# SF32LB57x register map
File version: 1.0
CPU: CM33 r0p1, little endian, MPU, FPU, 3 interrupt priority bits
Registers are 32-bit, read-write, reset 0x0 unless marked. A register's access mark holds for its fields unless they carry their own. Offsets are from the block's base; [hi:lo] are bit positions.

## LPTIM1
Base 0x500C1000
Same registers: LPTIM3 0x40042000, LPTIM2 0x500C2000
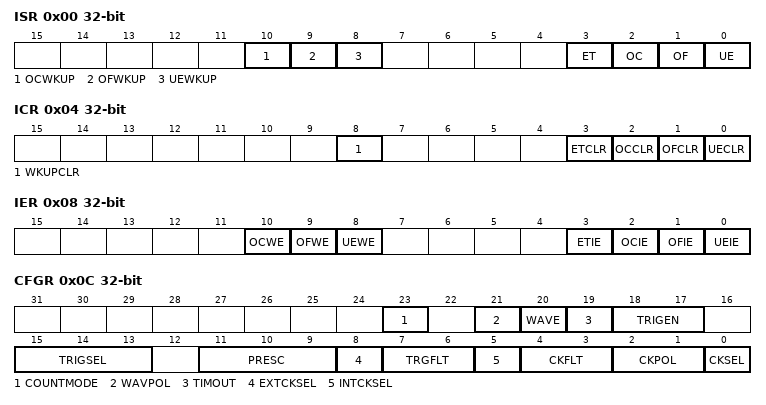
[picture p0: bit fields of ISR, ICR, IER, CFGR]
0x00 ISR — LPTIM interrupt and status register
  [10] OCWKUP — Indicates output compare wakeup occurred The OCWKUP bit is set by hardware when LPTIM_CNT register value reached the LPTIM_CMP register’s value. To clear OCWKUP, first write 0 to the OCWE bit in the LPTIM_IER register to disable, then write 1 to the WKUPCLR bit in the LPTIM_ICR register.
  [9] OFWKUP — Indicates overflow wakeup occurred OFWKUP is set by hardware when LPTIM_CNT register’s value reached the LPTIM_ARR register’s value and count from zero again. To clear OFWKUP, first write 0 to the OFWE bit in the LPTIM_IER register to disable, then write 1 to the WKUPCLR bit in the LPTIM_ICR register.
  [8] UEWKUP — Indicates update event wakeup occurred UEWKUP is set by hardware when an update event was generated (overflow occurred while repetition counter reached zero). To clear UEWKUP, first write 0 to the UEWE bit in the LPTIM_IER register to disable, then write 1 to the WKUPCLR bit in the LPTIM_ICR register.
  [3] ET — External trigger edge event ET is set by hardware to inform application that a valid edge on the selected external trigger input has occurred. If the trigger is ignored because the timer has already started, then this flag is not set. ET flag can be cleared by writing 1 to the ETCLR bit in the LPTIM_ICR register.
  [2] OC — Output compare match The OC bit is set by hardware to inform application that LPTIM_CNT register value reached the LPTIM_CMP register’s value. OC flag can be cleared by writing 1 to the OCCLR bit in the LPTIM_ICR register.
  [1] OF — Overflow occurred OF is set by hardware to inform application that LPTIM_CNT register’s value reached the LPTIM_ARR register’s value and count from zero again. OF flag can be cleared by writing 1 to the OFCLR bit in the LPTIM_ICR register.
  [0] UE — LPTIM update event occurred UE is set by hardware to inform application that an update event was generated when overflow occurred while repetition counter reached zero. UE flag can be cleared by writing 1 to the UECLR bit in the LPTIM_ICR register.
0x04 ICR — LPTIM interrupt and status clear register
  [8] WKUPCLR — wakeup status clear flag Writing 1 to this bit clears all wakeup status flags in the LPTIM_ISR register.
  [3] ETCLR — External trigger valid edge clear flag Writing 1 to this bit clears the ET flag in the LPTIM_ISR register
  [2] OCCLR — Output compare clear flag Writing 1 to this bit clears the OC flag in the LPTIM_ISR register
  [1] OFCLR — Overflow clear flag Writing 1 to this bit clears the OF flag in the LPTIM_ISR register
  [0] UECLR — Update event clear flag Writing 1 to this bit clear the UE flag in the LPTIM_ISR register.
0x08 IER — LPTIM interrupt and wakeup enable register
  [10] OCWE — Output compare Wakeup Enable 0: Output compare wakeup disabled 1: Output compare wakeup enabled
  [9] OFWE — Overflow Wakeup Enable 0: Overflow Wakeup disabled 1: Overflow Wakeup enabled
  [8] UEWE — Update event Wakeup enable 0: Update event Wakeup disabled 1: Update event Wakeup enabled
  [3] ETIE — External trigger valid edge Interrupt Enable 0: External trigger interrupt disabled 1: External trigger interrupt enabled
  [2] OCIE — Output compare Interrupt Enable 0: Output compare interrupt disabled 1: Output compare interrupt enabled
  [1] OFIE — Overflow Interrupt Enable 0: Overflow interrupt disabled 1: Overflow interrupt enabled
  [0] UEIE — Update event interrupt enable 0: Update event interrupt disabled 1: Update event interrupt enabled
0x0C CFGR — LPTIM configuration register
  [23] COUNTMODE — counter mode enabled The COUNTMODE bit selects which clock source is used by the LPTIM to clock the counter: 0: the counter is incremented following each internal clock pulse 1: the counter is incremented following each valid clock pulse on the LPTIM external Input1
  [21] WAVPOL — Waveform shape polarity The WAVEPOL bit controls the output polarity 0: The LPTIM output reflects the compare results between LPTIM_ARR and LPTIM_CMP registers 1: The LPTIM output reflects the inverse of the compare results between LPTIM_ARR and LPTIM_CMP registers
  [20] WAVE — Waveform shape The WAVE bit controls the output shape 0: Deactivate Set-once mode, PWM / One Pulse waveform (depending on OPMODE bit) 1: Activate the Set-once mode
  [19] TIMOUT — Timeout enable The TIMOUT bit controls the Timeout feature 0: A trigger event arriving when the timer is already started will be ignored 1: A trigger event arriving when the timer is already started will reset and restart the LPTIM counter and the repetition counter
  [18:17] TRIGEN — Trigger enable and polarity The TRIGEN bits controls whether the LPTIM counter is started by an external trigger or not. If the external trigger option is selected, three configurations are possible for the trigger active edge: 00: software trigger (counting start is initiated by software) 01: rising edge is the active edge 10: falling edge is the active edge 11: both edges are active edges
  [15:13] TRIGSEL — Trigger selector The TRIGSEL bits select the trigger source that will serve as a trigger event for the LPTIM among the below 8 available sources: 000: lptim_ext_trig0 001: lptim_ext_trig1 010: lptim_ext_trig2 011: lptim_ext_trig3 100: lptim_ext_trig4 101: lptim_ext_trig5 110: lptim_ext_trig6 111: lptim_ext_trig7
  [11:9] PRESC — Clock prescaler The PRESC bits configure the prescaler division factor. It can be one among the following division factors: 000: /1 001: /2 010: /4 011: /8 100: /16 101: /32 110: /64 111: /128
  [8] EXTCKSEL — External clock source selector 0: external clock source is from IO 1: external clock source is from COMP
  [7:6] TRGFLT — Configurable digital filter for trigger The TRGFLT value sets the number of consecutive equal samples that should be detected when a level change occurs on an internal trigger before it is considered as a valid level transition. An internal clock source must be present to use this feature 00: any trigger active level change is considered as a valid trigger 01: trigger active level change must be stable for at least 2 clock periods before it is considered as valid trigger. 10: trigger active level change must be stable for at least 4 clock periods before it is considered as valid trigger. 11: trigger active level change must be stable for at least 8 clock periods before it is considered as valid trigger.
  [5] INTCKSEL — Internal clock source selector 0: internal clock source is lp_clk 1: internal clock source is APB clock
  [4:3] CKFLT — Configurable digital filter for external clock The CKFLT value sets the number of consecutive equal samples that should be detected when a level change occurs on an external clock signal before it is considered as a valid level transition. An internal clock source must be present to use this feature 00: any external clock signal level change is considered as a valid transition 01: external clock signal level change must be stable for at least 2 clock periods before it is considered as valid transition. 10: external clock signal level change must be stable for at least 4 clock periods before it is considered as valid transition. 11: external clock signal level change must be stable for at least 8 clock periods before it is considered as valid transition.
  [2:1] CKPOL — Clock Polarity If LPTIM is clocked by an external clock source: When the LPTIM is clocked by an external clock source, CKPOL bits is used to configure the active edge or edges used by the counter: 00: the rising edge is the active edge used for counting 01: the falling edge is the active edge used for counting 10: both edges are active edges. When both external clock signal edges are considered active ones, the LPTIM must also be clocked by an internal clock source with a frequency equal to at least four time the external clock frequency. 11: not allowed
  [0] CKSEL — Clock selector The CKSEL bit selects which clock source the LPTIM will use: 0: LPTIM is clocked by internal clock source (APB clock or any of the embedded oscillators) 1: LPTIM is clocked by an external clock source through the LPTIM external Input1
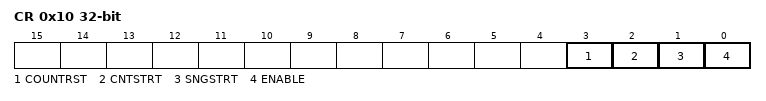
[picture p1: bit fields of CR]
0x10 CR — LPTIM control register
  [3] COUNTRST — Counter reset This bit is set by software and cleared by hardware. When set to '1' this bit will trigger a synchronous reset of the LPTIM_CNT counter register. Due to the synchronous nature of this reset, it only takes place after a synchronization delay of 3 LPTimer core clock cycles (LPTimer core clock may be different from APB clock). Caution: COUNTRST must never be set to '1' by software before it is already cleared to '0' by hardware. Software should consequently check that COUNTRST bit is already cleared to '0' before attempting to set it to '1'.
  [2] CNTSTRT — Timer start in Continuous mode This bit is set by software and cleared by hardware. In case of software start (TRIGEN[1:0] = ‘00’), setting this bit starts the LPTIM in Continuous mode. If the software start is disabled (TRIGEN[1:0] different than ‘00’), setting this bit starts the timer in Continuous mode as soon as an external trigger is detected. If this bit is set when a single pulse mode counting is ongoing, then the timer will not stop at the next match between the LPTIM_ARR and LPTIM_CNT registers and the LPTIM counter keeps counting in Continuous mode. This bit can be set only when the LPTIM is enabled. It will be automatically reset by hardware.
  [1] SNGSTRT — LPTIM start in Single mode This bit is set by software and cleared by hardware. In case of software start (TRIGEN[1:0] = ‘00’), setting this bit starts the LPTIM in single pulse mode. If the software start is disabled (TRIGEN[1:0] different than ‘00’), setting this bit starts the LPTIM in single pulse mode as soon as an external trigger is detected. If this bit is set when the LPTIM is in continuous counting mode, then the LPTIM will stop at the following match between LPTIM_ARR and LPTIM_CNT registers. This bit can only be set when the LPTIM is enabled. It will be automatically reset by hardware. If this bit is set simultaneously with CNTSTRT, then LPTIM will be in continuous counting mode.
  [0] ENABLE — LPTIM enable The ENABLE bit is set and cleared by software. 0:LPTIM is disabled 1:LPTIM is enabled
0x14 CMP — LPTIM compare register
  [23:0] CMP — Compare value CMP is the compare value used by the LPTIM.
0x18 ARR — LPTIM autoreload register
  [23:0] ARR — Auto reload value ARR is the autoreload value for the LPTIM.This value must be strictly greater than the CMP[15:0] value.
0x1C CNT — LPTIM counter register
  [23:0] CNT — Counter value When the LPTIM is running with an asynchronous clock, reading the LPTIM_CNT register may return unreliable values. So in this case it is necessary to perform two consecutive read accesses and verify that the two returned values are identical. It should be noted that for a reliable LPTIM_CNT register read access, two consecutive read accesses must be performed and compared. A read access can be considered reliable when the values of the two consecutive read accesses are equal.
0x20 RCR — LPTIM repetition register
  [7:0] REP — Repetition register value REP is the repetition value for the LPTIM. After configuration, new REP will not be reloaded until next counter reset or update event. Read REP will return left repetition times. It should be noted that for a reliable REP register read access, two consecutive read accesses must be performed and compared. A read access can be considered reliable when the values of the two consecutive read accesses are equal.
